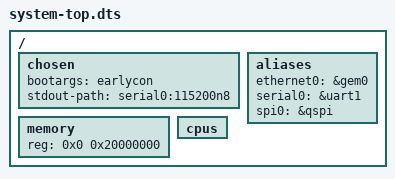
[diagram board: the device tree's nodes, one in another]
/*
 * CAUTION: This file is automatically generated by Xilinx.
 * Version: XSCT 2018.3
 * Today is: Thu Jun  3 12:51:47 2021
 */


/dts-v1/;
/include/ "zynq-7000.dtsi"
/include/ "pl.dtsi"
/include/ "pcw.dtsi"
/ {
	chosen {
		bootargs = "earlycon";
		stdout-path = "serial0:115200n8";
	};
	aliases {
		ethernet0 = &gem0;
		serial0 = &uart1;
		spi0 = &qspi;
	};
	memory {
		device_type = "memory";
		reg = <0x0 0x20000000>;
	};
	cpus {
		/delete-node/ cpu@0 ;
		/delete-node/ cpu@1 ;
	};
};
